AUTOSAR XML (schema 4-2-2)
package /System
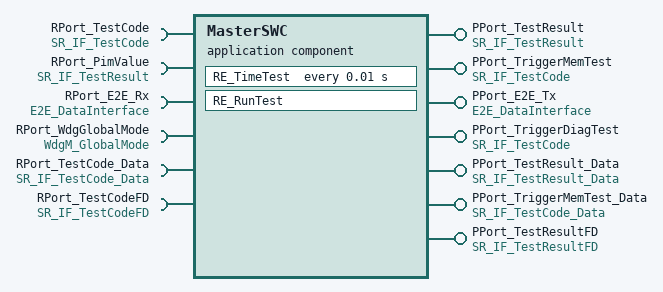
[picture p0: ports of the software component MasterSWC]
  application sw component type MasterSWC
    provide port PPort_TestResult: provided-interface=SR_IF_TestResult
    require port RPort_TestCode: required-interface=SR_IF_TestCode
    provide port PPort_TriggerMemTest: provided-interface=SR_IF_TestCode
    require port RPort_PimValue: required-interface=SR_IF_TestResult
    provide port PPort_E2E_Tx: provided-interface=E2E_DataInterface
    require port RPort_E2E_Rx: required-interface=E2E_DataInterface
    provide port PPort_TriggerDiagTest: provided-interface=SR_IF_TestCode
    require port RPort_WdgGlobalMode: required-interface=WdgM_GlobalMode
    provide port PPort_TestResult_Data: provided-interface=SR_IF_TestResult_Data
    require port RPort_TestCode_Data: required-interface=SR_IF_TestCode_Data
    provide port PPort_TriggerMemTest_Data: provided-interface=SR_IF_TestCode_Data
    provide port PPort_TestResultFD: provided-interface=SR_IF_TestResultFD
    require port RPort_TestCodeFD: required-interface=SR_IF_TestCodeFD
    behavior InternalBehavior: data-type-mapping=[DataTypeMappingSet_ASW, WdgM_ModeRequestTypeMap, WdgM_Type_Map]
      data received event DRE_TestCode: start-on-event=RE_RunTest, data=RPort_TestCode.TestCode
      data received event DRE_E2E: start-on-event=RE_RunTest, data=RPort_E2E_Rx.Data
      data received event DRE_PimValue: start-on-event=RE_RunTest, data=RPort_PimValue.TestResult
      timing event TE_Time_Period: start-on-event=RE_TimeTest, period=0.01
      data received event DRE_TestCodeFD: start-on-event=RE_RunTest, data=RPort_TestCodeFD.TestCode_FD
      runnable RE_RunTest: mode-access-point=RPort_WdgGlobalMode.currentMode
        data-receive-point-by-arguments:
          7 x access:
            DRATestCode: accessed-variable=RPort_TestCode.TestCode
            DRAE2E_Cks: accessed-variable=RPort_E2E_Rx.CKS
            DRAE2E_Data: accessed-variable=RPort_E2E_Rx.Data
            DRAE2E_Alive_Cnt: accessed-variable=RPort_E2E_Rx.Alive_Cnt
            DRA_TestResult_0: accessed-variable=RPort_PimValue.TestResult
            DRATestCodeData: accessed-variable=RPort_TestCode_Data.TestCode_Data
            DRPA_TestCode_FD_0: accessed-variable=RPort_TestCodeFD.TestCode_FD
        data-send-points:
          9 x access:
            DWATestResult: accessed-variable=PPort_TestResult.TestResult
            DWAE2E_Cks: accessed-variable=PPort_E2E_Tx.CKS
            DWAE2E_Data: accessed-variable=PPort_E2E_Tx.Data
            DWAE2E_Alive_Cnt: accessed-variable=PPort_E2E_Tx.Alive_Cnt
            DWA_TestCode_0: accessed-variable=PPort_TriggerMemTest.TestCode
            DSP_TestCode_0: accessed-variable=PPort_TriggerDiagTest.TestCode
            DWATestResultData: accessed-variable=PPort_TestResult_Data.TestResult_Data
            DSP_TestCode_Data_0: accessed-variable=PPort_TriggerMemTest_Data.TestCode_Data
            DSP_TestResult_FD_0: accessed-variable=PPort_TestResultFD.TestResult_FD
      runnable RE_TimeTest
